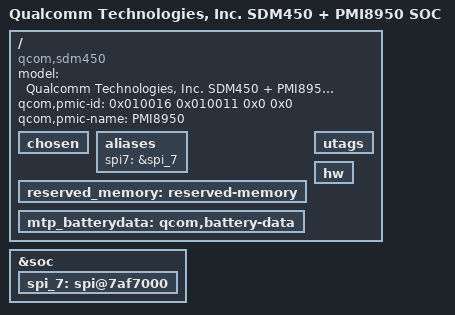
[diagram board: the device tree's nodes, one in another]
/* Copyright (c) 2018, The Linux Foundation. All rights reserved.
 *
 * This program is free software; you can redistribute it and/or modify
 * it under the terms of the GNU General Public License version 2 and
 * only version 2 as published by the Free Software Foundation.
 *
 * This program is distributed in the hope that it will be useful,
 * but WITHOUT ANY WARRANTY; without even the implied warranty of
 * MERCHANTABILITY or FITNESS FOR A PARTICULAR PURPOSE.  See the
 * GNU General Public License for more details.
 */

#include "sdm450.dtsi"
#include "pmi8950.dtsi"
#include "msm8953-pmi8950.dtsi"

&soc {
	spi_7: spi@7af7000 { };
};

/ {
/*
 * Some nodes need labels assigned to appear in __symbols__
 */
	model = "Qualcomm Technologies, Inc. SDM450 + PMI8950 SOC";
	compatible = "qcom,sdm450";
	qcom,pmic-id = <0x010016 0x010011 0x0 0x0>;
	qcom,pmic-name = "PMI8950";

	chosen: chosen { };
	aliases: aliases {
		spi7 = &spi_7;
	};
	reserved_memory: reserved-memory { };
	mtp_batterydata: qcom,battery-data {};
	utags: utags { };
	hw: hw { };
};

